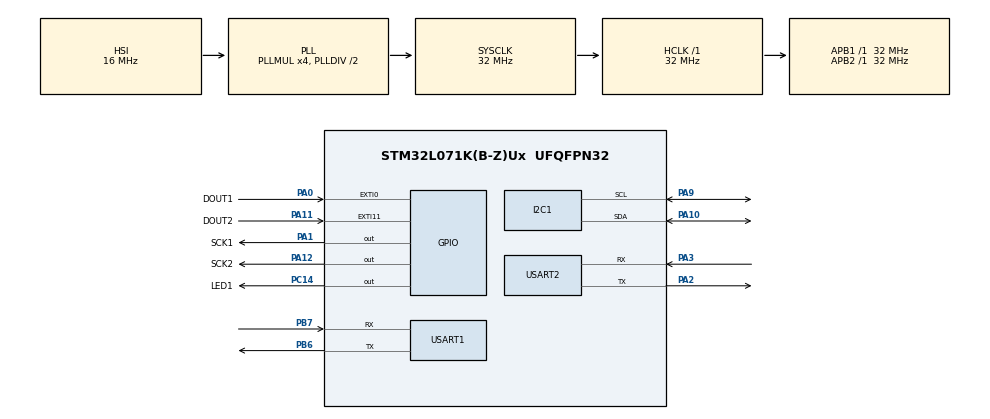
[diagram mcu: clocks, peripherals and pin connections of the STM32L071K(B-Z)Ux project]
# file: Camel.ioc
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CRC.CRCLength=CRC_POLYLENGTH_8B
CRC.DefaultInitValueUse=DEFAULT_INIT_VALUE_DISABLE
CRC.DefaultPolynomialUse=DEFAULT_POLYNOMIAL_DISABLE
CRC.GeneratingPolynomial=X7+X4+X2+X1+X0
CRC.InitValue=0xFF
Dma.Request0=USART1_TX
Dma.Request1=USART1_RX
Dma.Request2=USART2_TX
Dma.Request3=USART2_RX
Dma.USART1_RX.1.Direction=DMA_PERIPH_TO_MEMORY
Dma.USART1_RX.1.Instance=DMA1_Channel3
Dma.USART1_RX.1.MemDataAlignment=DMA_MDATAALIGN_BYTE
Dma.USART1_RX.1.MemInc=DMA_MINC_ENABLE
Dma.USART1_RX.1.Mode=DMA_CIRCULAR
Dma.USART1_RX.1.PeriphDataAlignment=DMA_PDATAALIGN_BYTE
Dma.USART1_RX.1.PeriphInc=DMA_PINC_DISABLE
Dma.USART1_RX.1.Priority=DMA_PRIORITY_LOW
Dma.USART1_TX.0.Direction=DMA_MEMORY_TO_PERIPH
Dma.USART1_TX.0.Instance=DMA1_Channel2
Dma.USART1_TX.0.MemDataAlignment=DMA_MDATAALIGN_BYTE
Dma.USART1_TX.0.MemInc=DMA_MINC_ENABLE
Dma.USART1_TX.0.Mode=DMA_NORMAL
Dma.USART1_TX.0.PeriphDataAlignment=DMA_PDATAALIGN_BYTE
Dma.USART1_TX.0.PeriphInc=DMA_PINC_DISABLE
Dma.USART1_TX.0.Priority=DMA_PRIORITY_LOW
Dma.USART2_RX.3.Direction=DMA_PERIPH_TO_MEMORY
Dma.USART2_RX.3.Instance=DMA1_Channel5
Dma.USART2_RX.3.MemDataAlignment=DMA_MDATAALIGN_BYTE
Dma.USART2_RX.3.MemInc=DMA_MINC_ENABLE
Dma.USART2_RX.3.Mode=DMA_CIRCULAR
Dma.USART2_RX.3.PeriphDataAlignment=DMA_PDATAALIGN_BYTE
Dma.USART2_RX.3.PeriphInc=DMA_PINC_DISABLE
Dma.USART2_RX.3.Priority=DMA_PRIORITY_LOW
Dma.USART2_TX.2.Direction=DMA_MEMORY_TO_PERIPH
Dma.USART2_TX.2.Instance=DMA1_Channel4
Dma.USART2_TX.2.MemDataAlignment=DMA_MDATAALIGN_BYTE
Dma.USART2_TX.2.MemInc=DMA_MINC_ENABLE
Dma.USART2_TX.2.Mode=DMA_NORMAL
Dma.USART2_TX.2.PeriphDataAlignment=DMA_PDATAALIGN_BYTE
Dma.USART2_TX.2.PeriphInc=DMA_PINC_DISABLE
Dma.USART2_TX.2.Priority=DMA_PRIORITY_LOW
FREERTOS.Tasks01=defaultTask,24,128,StartDefaultTask,As weak,NULL,Dynamic,NULL,NULL;consoleTask,15,320,StartConsoleTask,As external,NULL,Dynamic,NULL,NULL;hostCommTask,16,128,StartCommTask,As external,NULL,Dynamic,NULL,NULL;indicatorTask,8,192,StartIndicatorTask,As external,NULL,Dynamic,NULL,NULL
FREERTOS.configTOTAL_HEAP_SIZE=5120
FREERTOS.configUSE_NEWLIB_REENTRANT=1
I2C1.OwnAddress=CAMEL_ADDRESS
I2C1.Timing=0x00B07CB4
Mcu.Family=STM32L0
Mcu.Name=STM32L071K(B-Z)Ux
Mcu.Package=UFQFPN32
Mcu.UserConstants=CAMEL_ADDRESS,0x75
NVIC.DMA1_Channel2_3_IRQn=true\:3\:0\:false\:false\:true\:true\:false\:true\:true
NVIC.DMA1_Channel4_5_6_7_IRQn=true\:3\:0\:false\:false\:true\:true\:false\:true\:true
NVIC.EXTI0_1_IRQn=true\:3\:0\:false\:false\:true\:true\:true\:true\:true
NVIC.EXTI4_15_IRQn=true\:3\:0\:false\:false\:true\:true\:true\:true\:true
NVIC.I2C1_IRQn=true\:3\:0\:false\:false\:true\:true\:true\:true\:true
NVIC.TIM22_IRQn=true\:3\:0\:false\:false\:true\:false\:false\:true\:true
NVIC.TimeBase=TIM22_IRQn
NVIC.TimeBaseIP=TIM22
NVIC.USART1_IRQn=true\:3\:0\:false\:false\:true\:true\:true\:true\:true
NVIC.USART2_IRQn=true\:3\:0\:false\:false\:true\:true\:true\:true\:true
PA0.GPIO_Label=DOUT1
PA0.GPIO_ModeDefaultEXTI=GPIO_MODE_IT_FALLING
PA0.Signal=GPXTI0
PA1.GPIO_Label=SCK1
PA1.Signal=GPIO_Output
PA10.Mode=I2C
PA10.Signal=I2C1_SDA
PA11.GPIO_Label=DOUT2
PA11.GPIO_ModeDefaultEXTI=GPIO_MODE_IT_FALLING
PA11.Signal=GPXTI11
PA12.GPIO_Label=SCK2
PA12.Signal=GPIO_Output
PA13.Mode=Serial_Wire
PA13.Signal=SYS_SWDIO
PA14.Mode=Serial_Wire
PA14.Signal=SYS_SWCLK
PA2.Mode=Asynchronous
PA2.Signal=USART2_TX
PA3.Mode=Asynchronous
PA3.Signal=USART2_RX
PA9.Mode=I2C
PA9.Signal=I2C1_SCL
PB6.Mode=Asynchronous
PB6.Signal=USART1_TX
PB7.Mode=Asynchronous
PB7.Signal=USART1_RX
PC14-OSC32_IN.GPIO_Label=LED1
PC14-OSC32_IN.Signal=GPIO_Output
ProjectManager.HeapSize=0x200
ProjectManager.StackSize=0x400
ProjectManager.TargetToolchain=STM32CubeIDE
RCC.AHBFreq_Value=32000000
RCC.APB1Freq_Value=32000000
RCC.APB1TimFreq_Value=32000000
RCC.APB2Freq_Value=32000000
RCC.APB2TimFreq_Value=32000000
RCC.HCLKFreq_Value=32000000
RCC.HSI16_VALUE=16000000
RCC.HSI_VALUE=16000000
RCC.LSE_VALUE=32768
RCC.MSI_VALUE=2097000
RCC.PLLMUL=RCC_PLLMUL_4
RCC.SYSCLKFreq_VALUE=32000000
RCC.SYSCLKSource=RCC_SYSCLKSOURCE_PLLCLK
RCC.VCOOutputFreq_Value=64000000
USART1.VirtualMode-Asynchronous=VM_ASYNC
USART2.VirtualMode-Asynchronous=VM_ASYNC
VP_CRC_VS_CRC.Mode=CRC_Activate
VP_FREERTOS_VS_CMSIS_V2.Mode=CMSIS_V2
VP_SYS_VS_tim22.Mode=TIM22
board=custom

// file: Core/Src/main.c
/* USER CODE BEGIN Header */
/**
  ******************************************************************************
  * @file           : main.c
  * @brief          : Main program body
  ******************************************************************************
  * @attention
  *
  * Copyright (c) 2025 STMicroelectronics.
  * All rights reserved.
  *
  * This software is licensed under terms that can be found in the LICENSE file
  * in the root directory of this software component.
  * If no LICENSE file comes with this software, it is provided AS-IS.
  *
  ******************************************************************************
  */
/* USER CODE END Header */
#include "main.h"
#include "cmsis_os.h"

CRC_HandleTypeDef hcrc;

I2C_HandleTypeDef hi2c1;

UART_HandleTypeDef huart1;
UART_HandleTypeDef huart2;
DMA_HandleTypeDef hdma_usart1_tx;
DMA_HandleTypeDef hdma_usart1_rx;
DMA_HandleTypeDef hdma_usart2_tx;
DMA_HandleTypeDef hdma_usart2_rx;

/* Definitions for defaultTask */
osThreadId_t defaultTaskHandle;
const osThreadAttr_t defaultTask_attributes = {
  .name = "defaultTask",
  .stack_size = 128 * 4,
  .priority = (osPriority_t) osPriorityNormal,
};
/* Definitions for consoleTask */
osThreadId_t consoleTaskHandle;
const osThreadAttr_t consoleTask_attributes = {
  .name = "consoleTask",
  .stack_size = 320 * 4,
  .priority = (osPriority_t) osPriorityLow7,
};
/* Definitions for hostCommTask */
osThreadId_t hostCommTaskHandle;
const osThreadAttr_t hostCommTask_attributes = {
  .name = "hostCommTask",
  .stack_size = 128 * 4,
  .priority = (osPriority_t) osPriorityBelowNormal,
};
/* Definitions for indicatorTask */
osThreadId_t indicatorTaskHandle;
const osThreadAttr_t indicatorTask_attributes = {
  .name = "indicatorTask",
  .stack_size = 192 * 4,
  .priority = (osPriority_t) osPriorityLow,
};

void SystemClock_Config(void);
static void MX_GPIO_Init(void);
static void MX_DMA_Init(void);
static void MX_I2C1_Init(void);
static void MX_USART1_UART_Init(void);
static void MX_USART2_UART_Init(void);
static void MX_CRC_Init(void);
void StartDefaultTask(void *argument);
extern void StartConsoleTask(void *argument);
extern void StartCommTask(void *argument);
extern void StartIndicatorTask(void *argument);

int main(void)
{

  /* MCU Configuration--------------------------------------------------------*/

  /* Reset of all peripherals, Initializes the Flash interface and the Systick. */
  HAL_Init();

  /* Configure the system clock */
  SystemClock_Config();

  /* Initialize all configured peripherals */
  MX_GPIO_Init();
  MX_DMA_Init();
  MX_I2C1_Init();
  MX_USART1_UART_Init();
  MX_USART2_UART_Init();
  MX_CRC_Init();

  /* Init scheduler */
  osKernelInitialize();

  /* Create the thread(s) */
  /* creation of defaultTask */
  defaultTaskHandle = osThreadNew(StartDefaultTask, NULL, &defaultTask_attributes);

  /* creation of consoleTask */
  consoleTaskHandle = osThreadNew(StartConsoleTask, NULL, &consoleTask_attributes);

  /* creation of hostCommTask */
  hostCommTaskHandle = osThreadNew(StartCommTask, NULL, &hostCommTask_attributes);

  /* creation of indicatorTask */
  indicatorTaskHandle = osThreadNew(StartIndicatorTask, NULL, &indicatorTask_attributes);

  /* Start scheduler */
  osKernelStart();

  /* We should never get here as control is now taken by the scheduler */

  /* Infinite loop */
  while (1)
  {

    /* USER CODE BEGIN 3 */
    HAL_GPIO_TogglePin(LED1_GPIO_Port, LED1_Pin);
    HAL_Delay(400);
    HAL_GPIO_TogglePin(LED1_GPIO_Port, LED1_Pin);
    HAL_Delay(400);
  }
  /* USER CODE END 3 */
}

void SystemClock_Config(void)
{
  RCC_OscInitTypeDef RCC_OscInitStruct = {0};
  RCC_ClkInitTypeDef RCC_ClkInitStruct = {0};
  RCC_PeriphCLKInitTypeDef PeriphClkInit = {0};

  /** Configure the main internal regulator output voltage
  */
  __HAL_PWR_VOLTAGESCALING_CONFIG(PWR_REGULATOR_VOLTAGE_SCALE1);

  /** Initializes the RCC Oscillators according to the specified parameters
  * in the RCC_OscInitTypeDef structure.
  */
  RCC_OscInitStruct.OscillatorType = RCC_OSCILLATORTYPE_HSI;
  RCC_OscInitStruct.HSIState = RCC_HSI_ON;
  RCC_OscInitStruct.HSICalibrationValue = RCC_HSICALIBRATION_DEFAULT;
  RCC_OscInitStruct.PLL.PLLState = RCC_PLL_ON;
  RCC_OscInitStruct.PLL.PLLSource = RCC_PLLSOURCE_HSI;
  RCC_OscInitStruct.PLL.PLLMUL = RCC_PLLMUL_4;
  RCC_OscInitStruct.PLL.PLLDIV = RCC_PLLDIV_2;
  if (HAL_RCC_OscConfig(&RCC_OscInitStruct) != HAL_OK)
  {
    Error_Handler();
  }

  /** Initializes the CPU, AHB and APB buses clocks
  */
  RCC_ClkInitStruct.ClockType = RCC_CLOCKTYPE_HCLK|RCC_CLOCKTYPE_SYSCLK
                              |RCC_CLOCKTYPE_PCLK1|RCC_CLOCKTYPE_PCLK2;
  RCC_ClkInitStruct.SYSCLKSource = RCC_SYSCLKSOURCE_PLLCLK;
  RCC_ClkInitStruct.AHBCLKDivider = RCC_SYSCLK_DIV1;
  RCC_ClkInitStruct.APB1CLKDivider = RCC_HCLK_DIV1;
  RCC_ClkInitStruct.APB2CLKDivider = RCC_HCLK_DIV1;

  if (HAL_RCC_ClockConfig(&RCC_ClkInitStruct, FLASH_LATENCY_1) != HAL_OK)
  {
    Error_Handler();
  }
  PeriphClkInit.PeriphClockSelection = RCC_PERIPHCLK_USART1|RCC_PERIPHCLK_USART2
                              |RCC_PERIPHCLK_I2C1;
  PeriphClkInit.Usart1ClockSelection = RCC_USART1CLKSOURCE_PCLK2;
  PeriphClkInit.Usart2ClockSelection = RCC_USART2CLKSOURCE_PCLK1;
  PeriphClkInit.I2c1ClockSelection = RCC_I2C1CLKSOURCE_PCLK1;
  if (HAL_RCCEx_PeriphCLKConfig(&PeriphClkInit) != HAL_OK)
  {
    Error_Handler();
  }
}

static void MX_CRC_Init(void)
{

  hcrc.Instance = CRC;
  hcrc.Init.DefaultPolynomialUse = DEFAULT_POLYNOMIAL_DISABLE;
  hcrc.Init.DefaultInitValueUse = DEFAULT_INIT_VALUE_DISABLE;
  hcrc.Init.GeneratingPolynomial = 151;
  hcrc.Init.CRCLength = CRC_POLYLENGTH_8B;
  hcrc.Init.InitValue = 0xFF;
  hcrc.Init.InputDataInversionMode = CRC_INPUTDATA_INVERSION_NONE;
  hcrc.Init.OutputDataInversionMode = CRC_OUTPUTDATA_INVERSION_DISABLE;
  hcrc.InputDataFormat = CRC_INPUTDATA_FORMAT_BYTES;
  if (HAL_CRC_Init(&hcrc) != HAL_OK)
  {
    Error_Handler();
  }

}

static void MX_I2C1_Init(void)
{

  hi2c1.Instance = I2C1;
  hi2c1.Init.Timing = 0x00B07CB4;
  hi2c1.Init.OwnAddress1 = 234;
  hi2c1.Init.AddressingMode = I2C_ADDRESSINGMODE_7BIT;
  hi2c1.Init.DualAddressMode = I2C_DUALADDRESS_DISABLE;
  hi2c1.Init.OwnAddress2 = 0;
  hi2c1.Init.OwnAddress2Masks = I2C_OA2_NOMASK;
  hi2c1.Init.GeneralCallMode = I2C_GENERALCALL_DISABLE;
  hi2c1.Init.NoStretchMode = I2C_NOSTRETCH_DISABLE;
  if (HAL_I2C_Init(&hi2c1) != HAL_OK)
  {
    Error_Handler();
  }

  /** Configure Analogue filter
  */
  if (HAL_I2CEx_ConfigAnalogFilter(&hi2c1, I2C_ANALOGFILTER_ENABLE) != HAL_OK)
  {
    Error_Handler();
  }

  /** Configure Digital filter
  */
  if (HAL_I2CEx_ConfigDigitalFilter(&hi2c1, 0) != HAL_OK)
  {
    Error_Handler();
  }

}

static void MX_USART1_UART_Init(void)
{

  huart1.Instance = USART1;
  huart1.Init.BaudRate = 115200;
  huart1.Init.WordLength = UART_WORDLENGTH_8B;
  huart1.Init.StopBits = UART_STOPBITS_1;
  huart1.Init.Parity = UART_PARITY_NONE;
  huart1.Init.Mode = UART_MODE_TX_RX;
  huart1.Init.HwFlowCtl = UART_HWCONTROL_NONE;
  huart1.Init.OverSampling = UART_OVERSAMPLING_16;
  huart1.Init.OneBitSampling = UART_ONE_BIT_SAMPLE_DISABLE;
  huart1.AdvancedInit.AdvFeatureInit = UART_ADVFEATURE_NO_INIT;
  if (HAL_UART_Init(&huart1) != HAL_OK)
  {
    Error_Handler();
  }

}

static void MX_USART2_UART_Init(void)
{

  huart2.Instance = USART2;
  huart2.Init.BaudRate = 115200;
  huart2.Init.WordLength = UART_WORDLENGTH_8B;
  huart2.Init.StopBits = UART_STOPBITS_1;
  huart2.Init.Parity = UART_PARITY_NONE;
  huart2.Init.Mode = UART_MODE_TX_RX;
  huart2.Init.HwFlowCtl = UART_HWCONTROL_NONE;
  huart2.Init.OverSampling = UART_OVERSAMPLING_16;
  huart2.Init.OneBitSampling = UART_ONE_BIT_SAMPLE_DISABLE;
  huart2.AdvancedInit.AdvFeatureInit = UART_ADVFEATURE_NO_INIT;
  if (HAL_UART_Init(&huart2) != HAL_OK)
  {
    Error_Handler();
  }

}

static void MX_DMA_Init(void)
{

  /* DMA controller clock enable */
  __HAL_RCC_DMA1_CLK_ENABLE();

  /* DMA interrupt init */
  /* DMA1_Channel2_3_IRQn interrupt configuration */
  HAL_NVIC_SetPriority(DMA1_Channel2_3_IRQn, 3, 0);
  HAL_NVIC_EnableIRQ(DMA1_Channel2_3_IRQn);
  /* DMA1_Channel4_5_6_7_IRQn interrupt configuration */
  HAL_NVIC_SetPriority(DMA1_Channel4_5_6_7_IRQn, 3, 0);
  HAL_NVIC_EnableIRQ(DMA1_Channel4_5_6_7_IRQn);

}

static void MX_GPIO_Init(void)
{
  GPIO_InitTypeDef GPIO_InitStruct = {0};

  /* GPIO Ports Clock Enable */
  __HAL_RCC_GPIOC_CLK_ENABLE();
  __HAL_RCC_GPIOA_CLK_ENABLE();
  __HAL_RCC_GPIOB_CLK_ENABLE();

  /*Configure GPIO pin Output Level */
  HAL_GPIO_WritePin(LED1_GPIO_Port, LED1_Pin, GPIO_PIN_RESET);

  /*Configure GPIO pin Output Level */
  HAL_GPIO_WritePin(GPIOA, SCK1_Pin|SCK2_Pin, GPIO_PIN_RESET);

  /*Configure GPIO pin : LED1_Pin */
  GPIO_InitStruct.Pin = LED1_Pin;
  GPIO_InitStruct.Mode = GPIO_MODE_OUTPUT_PP;
  GPIO_InitStruct.Pull = GPIO_NOPULL;
  GPIO_InitStruct.Speed = GPIO_SPEED_FREQ_LOW;
  HAL_GPIO_Init(LED1_GPIO_Port, &GPIO_InitStruct);

  /*Configure GPIO pin : PC15 */
  GPIO_InitStruct.Pin = GPIO_PIN_15;
  GPIO_InitStruct.Mode = GPIO_MODE_ANALOG;
  GPIO_InitStruct.Pull = GPIO_NOPULL;
  HAL_GPIO_Init(GPIOC, &GPIO_InitStruct);

  /*Configure GPIO pins : DOUT1_Pin DOUT2_Pin */
  GPIO_InitStruct.Pin = DOUT1_Pin|DOUT2_Pin;
  GPIO_InitStruct.Mode = GPIO_MODE_IT_FALLING;
  GPIO_InitStruct.Pull = GPIO_NOPULL;
  HAL_GPIO_Init(GPIOA, &GPIO_InitStruct);

  /*Configure GPIO pins : SCK1_Pin SCK2_Pin */
  GPIO_InitStruct.Pin = SCK1_Pin|SCK2_Pin;
  GPIO_InitStruct.Mode = GPIO_MODE_OUTPUT_PP;
  GPIO_InitStruct.Pull = GPIO_NOPULL;
  GPIO_InitStruct.Speed = GPIO_SPEED_FREQ_LOW;
  HAL_GPIO_Init(GPIOA, &GPIO_InitStruct);

  /*Configure GPIO pins : PA4 PA5 PA6 PA7
                           PA8 */
  GPIO_InitStruct.Pin = GPIO_PIN_4|GPIO_PIN_5|GPIO_PIN_6|GPIO_PIN_7
                          |GPIO_PIN_8;
  GPIO_InitStruct.Mode = GPIO_MODE_ANALOG;
  GPIO_InitStruct.Pull = GPIO_NOPULL;
  HAL_GPIO_Init(GPIOA, &GPIO_InitStruct);

  /*Configure GPIO pins : PB0 PB1 PB4 PB5 */
  GPIO_InitStruct.Pin = GPIO_PIN_0|GPIO_PIN_1|GPIO_PIN_4|GPIO_PIN_5;
  GPIO_InitStruct.Mode = GPIO_MODE_ANALOG;
  GPIO_InitStruct.Pull = GPIO_NOPULL;
  HAL_GPIO_Init(GPIOB, &GPIO_InitStruct);

  /* EXTI interrupt init*/
  HAL_NVIC_SetPriority(EXTI0_1_IRQn, 3, 0);
  HAL_NVIC_EnableIRQ(EXTI0_1_IRQn);

  HAL_NVIC_SetPriority(EXTI4_15_IRQn, 3, 0);
  HAL_NVIC_EnableIRQ(EXTI4_15_IRQn);

}

__weak void StartDefaultTask(void *argument)
{
  for(;;)
  {
    osDelay(1);
  }
}

void HAL_TIM_PeriodElapsedCallback(TIM_HandleTypeDef *htim)
{
  if (htim->Instance == TIM22)
  {
    HAL_IncTick();
  }
}

void Error_Handler(void)
{
  __disable_irq();
  while (1)
  {
  }
}
